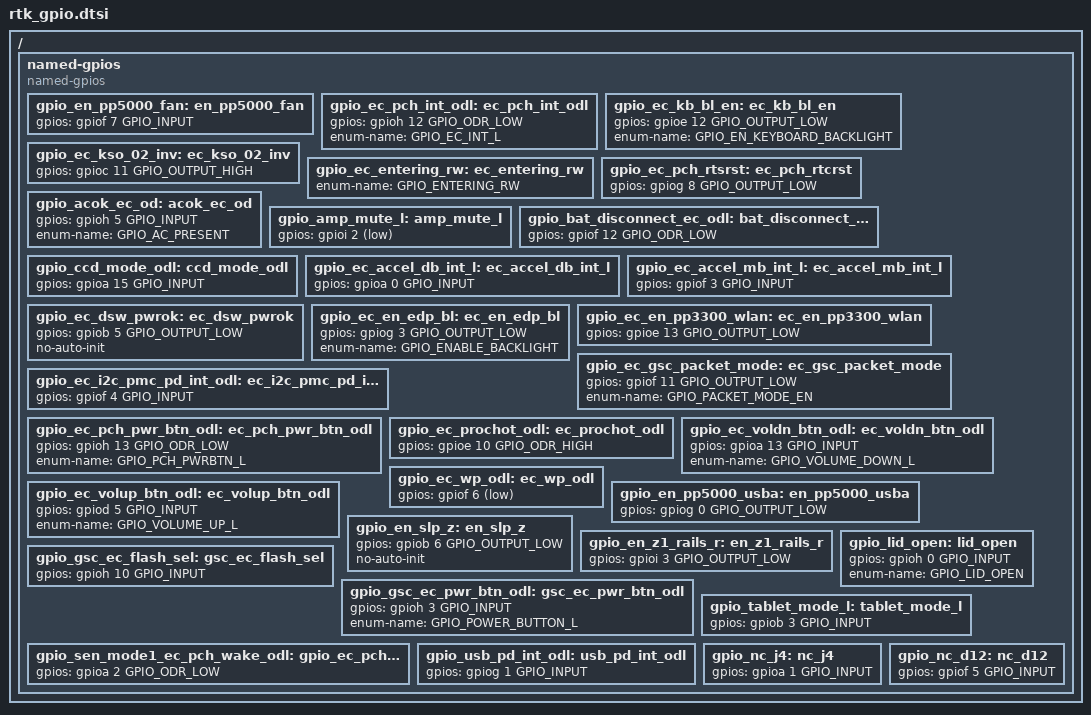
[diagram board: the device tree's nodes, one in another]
/* Copyright 2025 The ChromiumOS Authors
 * Use of this source code is governed by a BSD-style license that can be
 * found in the LICENSE file.
 */

/ {
	named-gpios {
		compatible = "named-gpios";

		gpio_en_pp5000_fan: en_pp5000_fan {
			gpios = <&gpiof 7 GPIO_INPUT>;
		};
		gpio_ec_pch_int_odl: ec_pch_int_odl {
			gpios = <&gpioh 12 GPIO_ODR_LOW>;
			enum-name = "GPIO_EC_INT_L";
		};
		gpio_ec_kb_bl_en: ec_kb_bl_en {
			gpios = <&gpioe 12 GPIO_OUTPUT_LOW>;
			enum-name = "GPIO_EN_KEYBOARD_BACKLIGHT";
		};
		gpio_ec_kso_02_inv: ec_kso_02_inv {
		 	gpios = <&gpioc 11 GPIO_OUTPUT_HIGH>;
		};
		/* The legacy system code requires GPIO_ENTERING_RW symbol */
		gpio_ec_entering_rw: ec_entering_rw {
			enum-name = "GPIO_ENTERING_RW";
		};
		/* EC_PCH_RTCRST_NC */
		gpio_ec_pch_rtsrst: ec_pch_rtcrst {
			gpios = <&gpiog 8 GPIO_OUTPUT_LOW>;
		};
		gpio_acok_ec_od: acok_ec_od {
			gpios = <&gpioh 5 GPIO_INPUT>;
		};
		gpio_amp_mute_l: amp_mute_l {
			gpios = <&gpioi 2 GPIO_OUTPUT_LOW>;
		};
		gpio_bat_disconnect_ec_odl: bat_disconnect_ec_odl {
			gpios = <&gpiof 12 GPIO_ODR_LOW>;
		};
		gpio_ccd_mode_odl: ccd_mode_odl {
			gpios = <&gpioa 15 GPIO_ODR_LOW>;
		};
		gpio_ec_accel_db_int_l: ec_accel_db_int_l {
			gpios = <&gpioa 0 GPIO_INPUT>;
		};
		gpio_ec_accel_mb_int_l: ec_accel_mb_int_l {
			gpios = <&gpiof 3 GPIO_INPUT>;
		};
		gpio_ec_batt_pres_odl: ec_batt_pres_odl {
			gpios = <&gpiof 1 GPIO_INPUT>;
			enum-name = "GPIO_BATT_PRES_ODL";
		};
		gpio_ec_dsw_pwrok: ec_dsw_pwrok {
			gpios = <&gpiob 5 GPIO_OUTPUT_LOW>;
			no-auto-init;
		};
		gpio_ec_en_edp_bl: ec_en_edp_bl {
			gpios = <&gpiog 3 GPIO_OUTPUT_LOW>;
			enum-name = "GPIO_ENABLE_BACKLIGHT";
		};
		gpio_ec_en_pp3300_wlan: ec_en_pp3300_wlan {
			gpios = <&gpioe 13 GPIO_OUTPUT_LOW>;
		};
		gpio_ec_gsc_packet_mode: ec_gsc_packet_mode {
		gpios = <&gpiof 11 GPIO_OUTPUT_LOW>;
			enum-name = "GPIO_PACKET_MODE_EN";
		};
		gpio_ec_i2c_pmc_pd_int_odl: ec_i2c_pmc_pd_int_odl {
			gpios = <&gpiof 4 GPIO_INPUT>;
		};
		gpio_ec_pch_pwr_btn_odl: ec_pch_pwr_btn_odl {
			gpios = <&gpioh 13 GPIO_ODR_LOW>;
			enum-name = "GPIO_PCH_PWRBTN_L";
		};
		gpio_ec_prochot_odl: ec_prochot_odl {
			gpios = <&gpioe 10 GPIO_ODR_LOW>;
		};
		gpio_ec_voldn_btn_odl: ec_voldn_btn_odl {
			gpios = <&gpioa 13 GPIO_INPUT>;
		};
		gpio_ec_volup_btn_odl: ec_volup_btn_odl {
			gpios = <&gpiod 5 GPIO_INPUT>;
		};
		gpio_ec_wp_odl: ec_wp_odl {
			gpios = <&gpiof 6 GPIO_INPUT>;
		};
		gpio_en_pp5000_usba: en_pp5000_usba {
			gpios = <&gpiog 0 GPIO_OUTPUT_LOW>;
		};
		gpio_en_slp_z: en_slp_z {
			gpios = <&gpiob 6 GPIO_OUTPUT_LOW>;
			/* GPIO initialized by hibernate_z5 driver. */
			no-auto-init;
		};
		gpio_en_z1_rails_r: en_z1_rails_r {
			gpios = <&gpioi 3 GPIO_OUTPUT_LOW>;
		};
		gpio_gsc_ec_flash_sel: gsc_ec_flash_sel {
			gpios = <&gpioh 10 GPIO_INPUT>;
		};
		gpio_gsc_ec_pwr_btn_odl: gsc_ec_pwr_btn_odl {
			gpios = <&gpioh 3 GPIO_INPUT>;
			enum-name = "GPIO_POWER_BUTTON_L";
		};
		gpio_lid_open: lid_open {
			gpios = <&gpioh 0 GPIO_INPUT>;
			enum-name = "GPIO_LID_OPEN";
		};
		gpio_sen_mode1_ec_pch_wake_odl: sen_mode1_ec_pch_wake_odl {
			gpios = <&gpioa 2 GPIO_ODR_LOW>;
		};
		gpio_tablet_mode_l: tablet_mode_l {
			gpios = <&gpiob 3 GPIO_INPUT>;
		};
		gpio_usb_pd_int_odl: usb_pd_int_odl {
			gpios = <&gpiog 1 GPIO_INPUT>;
		};

		/*
		 * In the Brox design these pins are tied to the EC power source,
		 * but RTS5915 does not need them, so set as inputs to prevent leakage.
		 */
		gpio_nc_j4: nc_j4 {
			gpios = <&gpioa 1 GPIO_INPUT>;
		};
		gpio_nc_d12: nc_d12 {
			gpios = <&gpiof 5 GPIO_INPUT>;
		};
	};
};

/* The eSPI shim requires this GPIO nodelabel */
gpio_ec_pch_wake_odl: &gpio_sen_mode1_ec_pch_wake_odl {
};

&gpio_ccd_mode_odl {
	gpios = <&gpioa 15 GPIO_INPUT>;
};

&gpio_amp_mute_l {
	gpios = <&gpioi 2 (GPIO_OUTPUT | GPIO_ACTIVE_LOW)>;
};

/* Default PROCHOT high so it's not asserted
 * TODO: b/214509787 - zephyr: subsys/ap_pwrseq: support chipset interface APIs
 */
&gpio_ec_prochot_odl {
	gpios = <&gpioe 10 GPIO_ODR_HIGH>;
};

&gpio_ec_voldn_btn_odl {
	enum-name = "GPIO_VOLUME_DOWN_L";
};

&gpio_ec_volup_btn_odl {
	enum-name = "GPIO_VOLUME_UP_L";
};

&gpio_ec_wp_odl {
	gpios = <&gpiof 6 (GPIO_INPUT | GPIO_ACTIVE_LOW) >;
};

&gpio_acok_ec_od {
	enum-name = "GPIO_AC_PRESENT";
};

/* BATT_PRES_ODL not connected on later board versions */
/delete-node/ &gpio_ec_batt_pres_odl;
